# netx90_app register map
File version: 1.0
CPU: CM4 r0p1, little endian, MPU, FPU, 4 interrupt priority bits, 78 interrupts
Registers are 32-bit, read-write, reset 0x0 unless marked. A register's access mark holds for its fields unless they carry their own. Offsets are from the block's base; [hi:lo] are bit positions; {n}, {i} and the like mark numbered series.

## hifmem_priority_ctrl
Base 0xFF401580
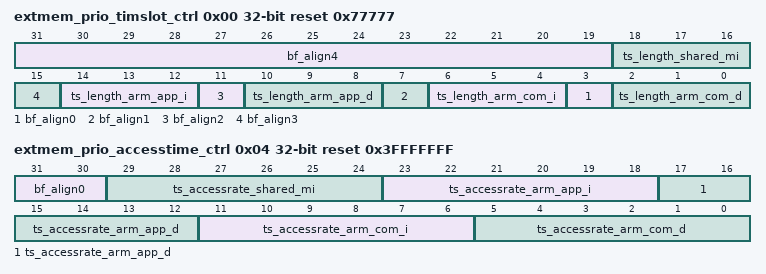
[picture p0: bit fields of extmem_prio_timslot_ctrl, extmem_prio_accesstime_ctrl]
0x00 extmem_prio_timslot_ctrl reset 0x77777 (reset mask 0x77777) — Memory interface master timeslot priority control register. Note: Any master can access in one timeslot ((ts_accessrate_mX*ts_length_mX)/64) + 1 times (i.e. at maximum (ts_accessrate_mX)/64 bandwidth on external memory bus, ts_accessrate_mX is programmed by extmem_prio_accesstime_ctrl-register). Priority control will watch data accesses on external memory data bus (SDRAM and non SDRAM), including pauses on non SDRAM-accesses, not including control commands to SDRAM. Any master requesting more accesses will be forced to wait for the remaining timeslot. -------------------------------------------------------- Programmable timeslots are: ts_length = 0 : 64 systen clock cycles (i.e 0.64us at 100MHz) ts_length = 1 : 128 systen clock cycles (i.e 1.28us at 100MHz) ts_length = 2 : 256 systen clock cycles (i.e 2.56us at 100MHz) ts_length = 3 : 512 systen clock cycles (i.e 5.12us at 100MHz) ts_length = 4 : 1024 systen clock cycles (i.e 10.24us at 100MHz) ts_length = 5 : 2048 systen clock cycles (i.e 20.48us at 100MHz) ts_length = 6 : 4096 systen clock cycles (i.e 40.96us at 100MHz) ts_length = 7 : 8192 systen clock cycles (i.e 81.92us at 100MHz) -------------------------------------------------------- For netX90 only SDRAM accesses are regarded for timeslot priority, SRAM/FLASH accesses are not. Note: This register can be protected by the register MODULE_FIREWALL_CTRL.firewall_cfg_hifmemctrl.
  [31:19] bf_align4 — bitField alignment value for aeabi compatibility
  [18:16] ts_length_shared_mi — 0..7: the timeslot of hifmem-master 4 is on external memory interface 64*2^ts_length_shared_mi systen clock cycles
  [4n+3] bf_align{n} (n=0..3) — bitField alignment value for aeabi compatibility
  [14:12] ts_length_arm_app_i — 0..7: the timeslot of hifmem-master 3 is on external memory interface 64*2^ts_length_arm_app_i systen clock cycles
  [10:8] ts_length_arm_app_d — 0..7: the timeslot of hifmem-master 2 is on external memory interface 64*2^ts_length_arm_app_d systen clock cycles
  [6:4] ts_length_arm_com_i — 0..7: the timeslot of hifmem-master 1 is on external memory interface 64*2^ts_length_arm_com_i systen clock cycles
  [2:0] ts_length_arm_com_d — 0..7: the timeslot of hifmem-master 0 is on external memory interface 64*2^ts_length_arm_com_d systen clock cycles
0x04 extmem_prio_accesstime_ctrl reset 0x3FFFFFFF (reset mask 0x3FFFFFFF) — Control Register for master channel accesses per timeslot on external meory interface. For detailed priority controlling read note at extmem_prio_timslot_ctrl-register description. -------------------------------------------------------- For netX90 only SDRAM accesses are regarded for timeslot priority, SRAM/FLASH accesses are not. Note: This register can be protected by the register MODULE_FIREWALL_CTRL.firewall_cfg_hifmemctrl.
  [31:30] bf_align0 — bitField alignment value for aeabi compatibility
  [29:24] ts_accessrate_shared_mi — 0..63: hifmem-master 4 is alowed to request ((ts_accessrate_shared_mi*ts_length_shared_mi)/64) + 1 accesses on external memory
  [23:18] ts_accessrate_arm_app_i — 0..63: hifmem-master 3 is alowed to request ((ts_accessrate_arm_app_i*ts_length_arm_app_i)/64) + 1 accesses on external memory
  [17:12] ts_accessrate_arm_app_d — 0..63: hifmem-master 2 is alowed to request ((ts_accessrate_arm_app_d*ts_length_arm_app_d)/64) + 1 accesses on external memory
  [11:6] ts_accessrate_arm_com_i — 0..63: hifmem-master 1 is alowed to request ((ts_accessrate_arm_com_i*ts_length_arm_com_i)/64) + 1 accesses on external memory
  [5:0] ts_accessrate_arm_com_d — 0..63: hifmem-master 0 is alowed to request ((ts_accessrate_arm_com_d*ts_length_arm_com_d)/64) + 1 accesses on external memory
